# CY8C5888LTI_LP097 register map
File version: 0.1
CY8C58LP
Registers are 8-bit, read-write, no defined reset value unless marked. A register's access mark holds for its fields unless they carry their own. Offsets are from the block's base; lines under a group give offsets from that group; [hi:lo] are bit positions; {n}, {i} and the like mark numbered series; 'fields as' and 'values as' point back to an identical list; <NAME> marks a mode.

## Memory map
0x00000000 Timer_1
0x00000000 Timer_0
0x00000000 LCD
0x00000000 DISPARADORES
0x00000000 btns

## Timer_1
Base 0x00000000
0x40006507 Timer_1_COUNTER — UDB.A0 - Current Down Counter Value
0x40006527 Timer_1_PERIOD — UDB.D0 - Assigned Period
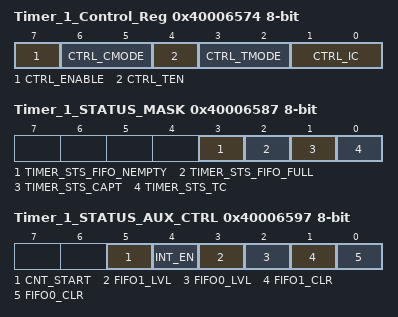
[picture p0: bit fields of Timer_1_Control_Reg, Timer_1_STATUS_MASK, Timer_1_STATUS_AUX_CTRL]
0x40006574 Timer_1_Control_Reg — UDB Control Register - Assigned Control Register Value
  [7] CTRL_ENABLE — Enable the Timer
  [6:5] CTRL_CMODE — Capture Mode
  [4] CTRL_TEN — Trigger Enable Bit
  [3:2] CTRL_TMODE — Trigger Mode
  [1:0] CTRL_IC — Interrupt Count
0x40006587 Timer_1_STATUS_MASK — UDB Status bits Interrupt Mask Enable Register
  [3] TIMER_STS_FIFO_NEMPTY ro — FIFO Empty status
  [2] TIMER_STS_FIFO_FULL ro — FIFO Full Status
  [1] TIMER_STS_CAPT ro — Enables the Interrupt on Capture
  [0] TIMER_STS_TC ro — Enables the Interrupt on TC
0x40006597 Timer_1_STATUS_AUX_CTRL — UDB Auxilliary Control Register
  [5] CNT_START — FIFO0 clear
    0=E_CNT_START0 (Disable counter); 1=E_CNT_START1 (Enable counter)
  [4] INT_EN
    0=E_INT_EN0 (Interrupt disabled); 1=E_INT_EN1 (Interrupt enabled)
  [3] FIFO1_LVL — FIFO level
    0=E_FIFO_LVL_0 (FIFO LVL: input mode: FIFO not full; output mode: FIFO not empty); 1=E_FIFO_LVL_1 (FIFO LVL: input mode: FIFO at least 1/2 empty; output mode: FIFO at least 1/2 full)
  [2] FIFO0_LVL — FIFO level
    values as FIFO1_LVL
  [1] FIFO1_CLR — FIFO1 clear
    0=E_FIFO_CLR_0 (Normal FIFO operation); 1=E_FIFO_CLR_1 (Clear FIFO state)
  [0] FIFO0_CLR — FIFO0 clear
    values as FIFO1_CLR

## Timer_0
Base 0x00000000
0x40006407 Timer_0_COUNTER — UDB.A0 - Current Down Counter Value
0x40006427 Timer_0_PERIOD — UDB.D0 - Assigned Period
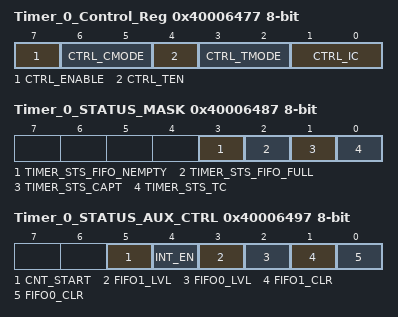
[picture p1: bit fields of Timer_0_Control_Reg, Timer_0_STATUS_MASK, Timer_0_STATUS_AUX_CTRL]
0x40006477 Timer_0_Control_Reg — UDB Control Register - Assigned Control Register Value
  [7] CTRL_ENABLE — Enable the Timer
  [6:5] CTRL_CMODE — Capture Mode
  [4] CTRL_TEN — Trigger Enable Bit
  [3:2] CTRL_TMODE — Trigger Mode
  [1:0] CTRL_IC — Interrupt Count
0x40006487 Timer_0_STATUS_MASK — UDB Status bits Interrupt Mask Enable Register
  fields as Timer_1.Timer_1_STATUS_MASK
0x40006497 Timer_0_STATUS_AUX_CTRL — UDB Auxilliary Control Register
  fields as Timer_1.Timer_1_STATUS_AUX_CTRL

## LCD
Base 0x00000000
0x40006575 LCD_CONTROL_REG

## DISPARADORES
Base 0x00000000
0x40006473 DISPARADORES_CONTROL_REG

## btns
Base 0x00000000
0x40006566 btns_STATUS_REG
0x40006586 btns_MASK_REG
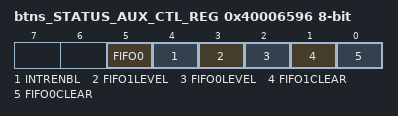
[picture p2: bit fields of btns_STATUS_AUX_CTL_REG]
0x40006596 btns_STATUS_AUX_CTL_REG
  [5] FIFO0 — FIFO0 clear
    1=ENABLED (Enable counter); 0=DISABLED (Disable counter)
  [4] INTRENBL — Enables or disables the Interrupt
    1=ENABLED (Interrupt enabled); 0=DISABLED (Interrupt disabled)
  [3] FIFO1LEVEL — FIFO level
    1=ENABLED (FIFO LVL: input mode: FIFO at least 1/2 empty; output mode: FIFO at least 1/2 full); 0=DISABLED (FIFO LVL: input mode: FIFO not full; output mode: FIFO not empty)
  [2] FIFO0LEVEL — FIFO level
    values as FIFO1LEVEL
  [1] FIFO1CLEAR — FIFO clear
    1=ENABLED (Clear FIFO state); 0=DISABLED (Normal FIFO operation)
  [0] FIFO0CLEAR — FIFO clear
    values as FIFO1CLEAR
